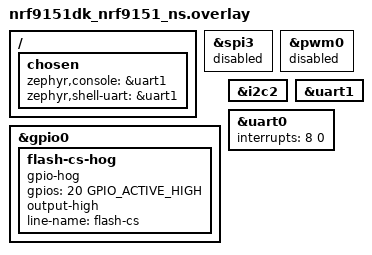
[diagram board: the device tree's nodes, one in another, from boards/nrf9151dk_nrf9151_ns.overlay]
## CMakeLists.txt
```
cmake_minimum_required(VERSION 3.20.0)

find_package(Zephyr REQUIRED HINTS $ENV{ZEPHYR_BASE})
project(nodem_zephyr)

target_sources(app PRIVATE
    src/main.c
    src/config_store.c
    src/display_task.c
    src/heartbeat_task.c
    src/hub75_task.c
    src/log.c
    src/modem_task.c
    src/nodem_config.c
    src/nodem_listener.c
    src/nodem_task.c
    src/ota_store.c
    src/pkg_store.c
    src/uart_task.c
)

# modem_task.c embeds the TLS root CA as a byte array via `#include
# "gts-root-r4.pem.inc"` - generate that from the PEM checked in under cert/.
set(modem_cert_gen_dir ${CMAKE_CURRENT_BINARY_DIR}/certs)
zephyr_include_directories(${modem_cert_gen_dir})
generate_inc_file_for_target(
    app
    cert/gts-root-r4.pem
    ${modem_cert_gen_dir}/gts-root-r4.pem.inc
    )

# `nodem-ffi` is built separately (`cargo build -p nodem-ffi --release --target
# thumbv8m.main-none-eabihf`, driven by the top-level `cargo run` wrapper
# before `west build` runs) - it isn't a CMake-built target, just a prebuilt
# static library to link in.
# Soft-float target: this app doesn't enable CONFIG_FPU, so Zephyr's own
# build is soft-float too - a hard-float (`...eabihf`) build of nodem-ffi
# fails to link (`uses VFP register arguments` / ARM EABI attribute mismatch).
set(NODEM_FFI_LIB
    ${CMAKE_CURRENT_SOURCE_DIR}/../nodem-ffi/target/thumbv8m.main-none-eabi/release/libnodem_ffi.a)

if(NOT EXISTS ${NODEM_FFI_LIB})
  message(FATAL_ERROR "nodem-ffi not built yet - run `cargo build -p nodem-ffi --release --target thumbv8m.main-none-eabi` first (expected at ${NODEM_FFI_LIB})")
endif()

# `zephyr_library_import`'s registration (a CMake global property consumed
# while `find_package(Zephyr)` processes zephyr/CMakeLists.txt) resolves
# before this file runs, so a library added that way silently never reaches
# the final link. Use a plain CMake imported target + `target_link_libraries`
# instead, per zephyr/samples/application_development/external_lib.
add_library(nodem_ffi STATIC IMPORTED GLOBAL)
set_target_properties(nodem_ffi PROPERTIES IMPORTED_LOCATION ${NODEM_FFI_LIB})
target_link_libraries(app PUBLIC nodem_ffi)
```

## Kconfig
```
#
# App-specific Kconfig - custom options live here, then "source
# Kconfig.zephyr" below pulls in the rest of Zephyr's own tree (required
# boilerplate for any app-level Kconfig root - see
# nrf/cmake/modules/kconfig.cmake: an app's own Kconfig file, if present,
# becomes KCONFIG_ROOT wholesale, not an addition to Zephyr's default one).
#

menu "nodem-nrf9151"

choice APP_LOG_LEVEL
	prompt "Application log level (log.h's info/warn/error/debug macros)"
	default APP_LOG_LEVEL_DEBUG
	help
	  Each level compiles in itself and everything more severe, same as
	  the `log` crate's max_level_* features nodem-ffi's Cargo.toml
	  mirrors this with (see the Makefile's LOG_LEVEL switch) - dropped
	  levels compile away to nothing (log.h's macros expand to a bare
	  ((void)0), not a runtime-filtered call), actually shrinking flash
	  usage rather than just quieting the console.

config APP_LOG_LEVEL_DEBUG
	bool "Debug and above (debug/info/warn/error)"

config APP_LOG_LEVEL_INFO
	bool "Info and above (info/warn/error)"

config APP_LOG_LEVEL_WARN
	bool "Warn and above (warn/error)"

config APP_LOG_LEVEL_ERROR
	bool "Error only"

config APP_LOG_LEVEL_NONE
	bool "No logging at all"

endchoice

endmenu

menu "Zephyr Kernel"
source "Kconfig.zephyr"
endmenu
```

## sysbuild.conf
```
# Builds MCUboot as its own sysbuild image alongside zephyr-app, splitting
# flash into two 320KB OTA slots (mcuboot_primary/mcuboot_secondary - see
# pm_static.yml for how their size is controlled indirectly) instead of the
# single monolithic TF-M+app image this project shipped with before. This
# just makes the two slots and the bootloader that swaps between them exist;
# streaming an update into the secondary slot and requesting the upgrade is
# src/ota_store.c's job (driven by nodem-ffi's control.rs, "ota" uploads).
SB_CONFIG_BOOTLOADER_MCUBOOT=y

# NCS v3.4.1+: Partition Manager (what pm_static.yml configures) is being
# phased out in favor of devicetree-based partitioning, and is no longer
# enabled by default for nRF91 boards specifically (unlike other SoC
# families, which still default it on for now) - explicit opt-in required,
# or the build silently gets no pm_config.h and every PM_*_ADDRESS/PM_*_SIZE
# consumer (pkg_store.c, the nonsecure_storage/settings_storage layout below)
# fails to compile. Revisit this whole file when actually migrating to DTS
# partitioning (see nrf/doc/.../migration_partitions.rst and
# nrf/scripts/pm_to_dts.py in the SDK) rather than treating this as permanent.
SB_CONFIG_PARTITION_MANAGER=y
```

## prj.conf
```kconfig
# Render nodem-rs's DOM runtime to the physical SSD1306 over I2C, and bring
# up the nRF9151 modem (modem_task.c) to reach the status endpoint over TLS.

# No CONFIG_DISPLAY - display_task.c talks to the SSD1306 directly over
# CONFIG_I2C, bypassing Zephyr's display subsystem entirely (its built-in
# ssd1306 driver produced garbled output on this panel).
CONFIG_I2C=y
CONFIG_GPIO=y

# TF-M's PSA Protected Storage and Internal Trusted Storage services are on
# by default but unused here - config_store.c goes through Zephyr's own
# settings/NVS against the "settings_storage" partition directly, never PSA's
# storage APIs. Turning these off drops tfm_ps/tfm_its/tfm_otp_nv_counters
# (Protected Storage's rollback-counter backing) entirely, along with the
# 32KB-SPU-alignment padding forced around each of those three small
# partitions - see pm_static.yml's own notes on why that space matters. That
# reclaimed ~96KB is what makes the two 320KB OTA slots (sysbuild.conf) fit
# at all under v3.4.1's TF-M. Considered porting device_secret specifically
# to PSA Protected Storage instead (real TF-M feature, would give it
# confidentiality/rollback protection) but decided against it: it costs back
# the same ~96KB, and its threat model (protects against a compromised NS
# app or flash-dump extraction) is largely moot anyway while
# UICR.APPROTECT/SECUREAPPROTECT are both left open for debugging (Makefile) -
# a physical SWD debugger can already read Secure flash/RAM directly. Staying
# on Zephyr's own settings/NVS.
CONFIG_TFM_PARTITION_PROTECTED_STORAGE=n
CONFIG_TFM_PARTITION_INTERNAL_TRUSTED_STORAGE=n

# TF-M's secure RAM - NCS's generic nRF91 default is 0x16000 (88KB), but
# this build's TF-M only statically uses ~37KB of it (all of it static: its
# stacks and mbedTLS heap included - see tfm_s.elf), mostly the crypto
# service (partition stack, mbedTLS heap, operation slots, iovec buffer),
# which this firmware barely uses (TLS is offloaded to the modem; only
# SHA-1 for the websocket handshake and RNG go through it). 48KB keeps
# ~11KB of headroom and is a multiple of the SPU's 8KB RAM region size
# (CONFIG_NRF_SPU_RAM_REGION_SIZE), which the secure/non-secure boundary
# has to fall on; the other 40KB goes to the app.
CONFIG_PM_PARTITION_SIZE_TFM_SRAM=0xC000

# TF-M's flash partition - Partition Manager's default is 0x17E00 (96KB less
# the 512-byte MCUboot header, three of the SPU's 32KB flash regions -
# CONFIG_NRF_TRUSTZONE_FLASH_REGION_SIZE), but this build's tfm_s.bin is only
# ~64.4KB: two regions (0xFE00 after the header) hold it with ~600 bytes to
# spare. The partition sits inside the signed image (mcuboot_primary holds
# TF-M and the app together), so its padding counted against the slot
# limit just like code - this hands those ~32KB to the app instead. The
# slot boundaries themselves don't move, so OTA between builds with and
# without this works. If TF-M ever grows past 0xFE00 (an NCS update, a TF-M
# partition turned back on - see above), the build fails at link/PM time,
# not silently: raise this back to 0x17E00 then.
CONFIG_PM_PARTITION_SIZE_TFM=0xFE00

CONFIG_MAIN_STACK_SIZE=4096
CONFIG_HEAP_MEM_POOL_SIZE=2048

# boot_write_img_confirmed()/boot_is_img_confirmed() (<zephyr/dfu/mcuboot.h>,
# used by heartbeat_task.c) - after `make flash-ota SLOT=1` lands a pending
# ("test") swap in the secondary slot (see the Makefile's own note),
# MCUboot boots it once without marking it permanent; if it's never
# confirmed before the next reset, MCUboot reverts back to the previous
# image automatically. This is what lets the new image call
# boot_write_img_confirmed() itself once it's proven stable, instead.
# IMG_MANAGER (the menuconfig gate) requires STREAM_FLASH; MCUBOOT_IMG_MANAGER
# is its only real choice and pulls in MCUBOOT_BOOTUTIL_LIB itself.
CONFIG_STREAM_FLASH=y
CONFIG_IMG_MANAGER=y
CONFIG_MCUBOOT_IMG_MANAGER=y
# ota_store.c erases mcuboot_secondary page by page as an upload streams in
# (and scrambles its MCUboot trailer before the first write), instead of
# erasing the whole 320KB slot up front - that takes several seconds, long
# enough to stall the uploader waiting for its CTR reply. Selects
# STREAM_FLASH_ERASE itself.
CONFIG_IMG_ERASE_PROGRESSIVELY=y

# nodem_listener.c's nodem_hw_reset() (the "#reset" command, via nodem-ffi's
# control.rs) needs sys_reboot().
CONFIG_REBOOT=y

# config_store.c - small flash-backed key/value store for persisted config
# (Settings on top of NVS). Enabling CONFIG_SETTINGS_NVS makes the partition
# manager reserve a "settings_storage" flash partition automatically - its
# address/size are pinned in pm_static.yml now (moved to reclaim what used
# to be pure alignment padding), but nothing here needed to change for that.
CONFIG_SETTINGS=y
CONFIG_SETTINGS_NVS=y
CONFIG_NVS=y
CONFIG_FLASH_MAP=y
CONFIG_FLASH=y

# pkg_store.c - raw staging partition for an uploaded nodem-rs binary
# UI/Media package (see pm_static.yml's "pkg" partition and control.rs's
# IControlLoader impl).
# CONFIG_FLASH_PAGE_LAYOUT is needed for flash_get_page_info_by_offs(), used
# there to find the flash's actual erase-page size rather than assuming one.
CONFIG_FLASH_PAGE_LAYOUT=y

# Modem library - modem_task.c calls nrf_modem_lib_init() itself (rather
# than relying on any auto-init), so enabling this alone doesn't touch the
# modem before main() runs.
CONFIG_NRF_MODEM_LIB=y

# LTE link control (registration/PDN bring-up) and the PDN library (default
# context activation events), used by modem_task.c to connect and to check
# SIM readiness (AT+CPIN? via nrf_modem_at.h) while offline.
CONFIG_LTE_LINK_CONTROL=y
CONFIG_LTE_LC_PDN_MODULE=y
CONFIG_LTE_LC_PDN_ESM_STRERROR=y

# Provisions the TLS root CA to the modem's key storage (modem-offloaded
# TLS - see IPPROTO_TLS_1_2 below - rather than a host-side TLS stack).
CONFIG_MODEM_KEY_MGMT=y

# Networking - offloaded sockets (the nRF9151 modem does TCP/TLS/DNS
# itself), no native netif needed.
CONFIG_NETWORKING=y
CONFIG_NET_NATIVE=n
CONFIG_NET_SOCKETS=y
CONFIG_NET_SOCKETS_OFFLOAD=y
CONFIG_NET_IPV4=y
CONFIG_NET_IPV6=y
CONFIG_POSIX_API=y

# Websocket client - modem_task.c's step_websocket_connect() layers this on
# top of the same offloaded TLS socket used for registration. NCS v3.4.1's
# Zephyr rewrote the RFC 6455 handshake to validate Sec-WebSocket-Accept via
# psa_hash_compute(PSA_ALG_SHA_1, ...) instead of calling mbedtls_sha1()
# directly like the older Zephyr this project shipped against under NCS
# v2.8.0 did (that older direct-call approach was why this project carried
# its own src/sha1_shim.c providing a standalone mbedtls_sha1() - removed
# now that nothing calls it anymore, see git history if ever needed again).
# PSA builds only compile in algorithms explicitly requested, and SHA-1 was
# never requested (only CONFIG_PSA_WANT_ALG_SHA_256, for TLS) since the old
# code path bypassed PSA for this entirely - without this,
# psa_hash_compute(PSA_ALG_SHA_1, ...) fails with PSA_ERROR_NOT_SUPPORTED,
# which websocket_connect() surfaces as -EPROTO.
CONFIG_PSA_WANT_ALG_SHA_1=y
CONFIG_WEBSOCKET_CLIENT=y

# printk() over the DK's onboard UART console - moved to uart1 (the board
# overlay's `chosen` override), wired through the J-Link's second USB
# virtual COM port (VCOM1), separate from both the SWD debug port and the
# process_command UART (uart0, see uart_task.c). RTT was abandoned: it
# requires an open SWD connection, which this board's TF-M setup re-locks
# on every boot, making RTT capture impossible without erasing (and thus
# stopping) the firmware each time. UART works regardless of the debug
# port's lock state.
CONFIG_SERIAL=y
CONFIG_CONSOLE=y
CONFIG_UART_CONSOLE=y

# Dedicated process_command UART (uart0) - interrupt-driven RX so
# uart_task.c's ISR can drain the FIFO into a ring buffer without losing
# bytes; nRF's UARTE has no real RX FIFO depth, so anything less than
# interrupt-driven (e.g. plain polling) drops bytes at any real baud rate.
CONFIG_UART_INTERRUPT_DRIVEN=y
CONFIG_RING_BUFFER=y
```

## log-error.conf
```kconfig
# Opt-in build fragment: drop debug()/info()/warn()-level logging, keep only
# error(). See zephyr-app/Kconfig (APP_LOG_LEVEL choice) and log.h. Applied
# via `LOG_LEVEL=error make build` (see the Makefile).
CONFIG_APP_LOG_LEVEL_ERROR=y
```

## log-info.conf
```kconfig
# Opt-in build fragment: drop debug()-level logging, keep info/warn/error.
# See zephyr-app/Kconfig (APP_LOG_LEVEL choice) and log.h. Applied via
# `LOG_LEVEL=info make build` (see the Makefile).
CONFIG_APP_LOG_LEVEL_INFO=y
```

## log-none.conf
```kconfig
# Opt-in build fragment: drop all of debug()/info()/warn()/error() logging
# and log_bytes(). See zephyr-app/Kconfig (APP_LOG_LEVEL choice) and log.h.
# Applied via `LOG_LEVEL=none make build` (see the Makefile).
CONFIG_APP_LOG_LEVEL_NONE=y
```

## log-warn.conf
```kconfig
# Opt-in build fragment: drop debug()/info()-level logging, keep warn/error.
# See zephyr-app/Kconfig (APP_LOG_LEVEL choice) and log.h. Applied via
# `LOG_LEVEL=warn make build` (see the Makefile).
CONFIG_APP_LOG_LEVEL_WARN=y
```

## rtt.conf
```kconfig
# Opt-in build fragment: view logs over RTT/SWD (`make logs-rtt`) instead of
# the default UART console (`make logs`). Applied on top of prj.conf via
# `-DEXTRA_CONF_FILE=rtt.conf` (see the Makefile's build-rtt target) into a
# separate build directory - the plain `make build`/`make logs` UART flow is
# untouched and stays the default; this is a second, parallel option, not a
# replacement.
#
# Needs CONFIG_UART_CONSOLE explicitly off: Zephyr's console drivers each
# install their own printk hook at init, so whichever one initializes last
# silently wins if both are left enabled - rather than depend on init-order
# behavior, this build variant is RTT-only.
#
# This only became viable once the debug port reliably stays open across a
# reset (see the Makefile's own note on UICR.APPROTECT/SECUREAPPROTECT) -
# RTT needs a live, unlocked SWD connection to read the target's RAM ring
# buffer, which is exactly what used to be locked after every boot.
CONFIG_USE_SEGGER_RTT=y
CONFIG_RTT_CONSOLE=y
CONFIG_UART_CONSOLE=n
```

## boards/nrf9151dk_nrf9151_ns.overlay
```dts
/*
 * spi3 (arduino_spi, enabled by default on this board) would claim
 * P0.11-P0.13 - disabled so those pins stay free for the HUB75 lines.
 * The DK's external flash still sits on them (CS = P0.20, flash node is
 * disabled in the base board dts).
 */
&spi3 {
	status = "disabled";
};

/* ...so hold the flash's CS high, or it could answer on P0.12 while the
 * HUB75 lines on P0.11-P0.13 are switching (see hub75_task.h). */
&gpio0 {
	flash-cs-hog {
		gpio-hog;
		gpios = <20 GPIO_ACTIVE_HIGH>;
		output-high;
		line-name = "flash-cs";
	};
};

/* P0.00 (pwm_led0, LED1) is HUB75's R1 - nothing uses pwm0, and a second
 * PWM instance claiming the same pin would fight hub75_task's. LED1 stays
 * main.c's heartbeat, as a plain GPIO (led0). */
&pwm0 {
	status = "disabled";
};

/* SSD1306 OLED on the board's arduino_i2c bus: P0.30 (SDA) / P0.31 (SCL),
 * Arduino D14/D15 - pinctrl and clock-frequency (I2C_BITRATE_FAST) already
 * come from the base board dts. No `ssd1306` child node here -
 * display_task.c talks to the panel directly over this bus with its own
 * hand-rolled driver. */
&i2c2 {
	status = "okay";
};

/* P0.28 (RX) / P0.29 (TX) - disabled by default on the `_ns` target ("used
 * by default in TF-M" per the base board dts), otherwise free. Pinctrl and
 * current-speed (115200) are already set correctly at the common board
 * level; this just re-enables it. Dedicated to console/log output only
 * (see log.h/prj.conf) - the `chosen` override below moves it here from
 * uart0, which is now dedicated to the process_command protocol instead
 * (see uart_task.c), so log text can never corrupt that protocol's framing
 * either way. */
&uart1 {
	status = "okay";
};

/* The process_command UART's (see uart_task.c) interrupt above everything
 * else: nRF's UARTE has next to no RX FIFO, and hub75_task.c's PWM interrupt
 * (priority 1, the same level this had by default, so it couldn't be preempted)
 * renders a whole row per run - long enough at full baud for the next bytes
 * to be lost, which stalled every upload ("pkg"/"ota") of more than a few KB. */
&uart0 {
	interrupts = <8 0>;
};

/ {
	chosen {
		zephyr,console = &uart1;
		zephyr,shell-uart = &uart1;
	};
};
```

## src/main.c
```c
/*
 * Entry point. The real work happens in display_task.c (owns the SSD1306
 * over I2C), nodem_task.c (renders nodem-rs at ~30Hz and hands frames to
 * display_task), and modem_task.c (LTE/TLS) - all self-start via
 * K_THREAD_DEFINE at kernel init, before main() runs. This initializes the
 * config store first (so those threads never race its first load), then
 * just blinks the LED as a liveness heartbeat.
 */

#include <zephyr/kernel.h>
#include <zephyr/device.h>
#include <zephyr/devicetree.h>
#include <zephyr/dfu/mcuboot.h>
#include <zephyr/drivers/gpio.h>

#include "config_store.h"
#include "heartbeat_task.h"
#include "log.h"

#define TAG "main"

#define LED0_NODE DT_ALIAS(led0)
static const struct gpio_dt_spec led = GPIO_DT_SPEC_GET(LED0_NODE, gpios);

int main(void)
{
	info(TAG, "main() entered");

	/* MCUboot always executes from the primary slot - there's no "running
	 * from slot 1" to report post-swap, the swap physically moves bytes
	 * into slot 0 before this ever runs. What *is* knowable: whether this
	 * boot is a freshly-swapped-in OTA image MCUboot is still only
	 * running as a one-time test (boot_is_img_confirmed() == false, see
	 * the Makefile's `flash-ota SLOT=1` and heartbeat_task.c's own note),
	 * or an already-confirmed image (either the original factory image,
	 * or a previously-confirmed OTA update - the two are indistinguishable
	 * from here once confirmed, since confirming doesn't record *when*). */
	if (boot_is_img_confirmed()) {
		info(TAG, "boot: image confirmed");
	} else {
		info(TAG, "boot: image pending - OTA test swap, reverts if not confirmed within %ds",
		     HEARTBEAT_OTA_CONFIRM_SECONDS);
	}

	int err = config_store_init();

	if (err) {
		error(TAG, "config_store_init failed, err %d", err);
	}

	if (!gpio_is_ready_dt(&led)) {
		error(TAG, "led device not ready");
		return 0;
	}
	gpio_pin_configure_dt(&led, GPIO_OUTPUT_INACTIVE);

	while (true) {
		gpio_pin_toggle_dt(&led);
		k_msleep(500);
	}

	return 0;
}
```

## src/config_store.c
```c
#include "config_store.h"

#include <string.h>
#include <stdio.h>
#include <errno.h>

#include <zephyr/kernel.h>
#include <zephyr/settings/settings.h>

#include "log.h"

#define TAG "config"

#define MAX_ENTRIES 16
#define MAX_KEY_LEN 15
#define MAX_STR_LEN 127

enum entry_type {
	ENTRY_STR,
	ENTRY_I32,
};

struct entry {
	bool used;
	enum entry_type type;
	char key[MAX_KEY_LEN + 1];
	union {
		char str[MAX_STR_LEN + 1];
		int32_t i32;
	} value;
};

static struct entry entries[MAX_ENTRIES];
static K_MUTEX_DEFINE(entries_lock);

/* Caller must hold entries_lock. Returns the existing entry for `key`/`type`,
 * or - if `create` - a freshly claimed one, or NULL if not found/no room. */
static struct entry *find_entry(const char *key, enum entry_type type, bool create)
{
	struct entry *free_slot = NULL;

	for (int i = 0; i < MAX_ENTRIES; i++) {
		if (entries[i].used && entries[i].type == type &&
		    strcmp(entries[i].key, key) == 0) {
			return &entries[i];
		}
		if (!entries[i].used && !free_slot) {
			free_slot = &entries[i];
		}
	}

	if (!create || !free_slot) {
		return NULL;
	}

	strncpy(free_slot->key, key, MAX_KEY_LEN);
	free_slot->key[MAX_KEY_LEN] = '\0';
	free_slot->type = type;
	free_slot->used = true;

	return free_slot;
}

static int settings_set(const char *name, size_t len, settings_read_cb read_cb, void *cb_arg)
{
	const char *sub_key;

	k_mutex_lock(&entries_lock, K_FOREVER);

	if (settings_name_steq(name, "s", &sub_key) && sub_key) {
		char buf[MAX_STR_LEN + 1] = { 0 };
		ssize_t n = read_cb(cb_arg, buf, sizeof(buf) - 1);
		struct entry *e;

		if (n < 0) {
			k_mutex_unlock(&entries_lock);
			return n;
		}

		e = find_entry(sub_key, ENTRY_STR, true);
		if (!e) {
			k_mutex_unlock(&entries_lock);
			return -ENOMEM;
		}

		memcpy(e->value.str, buf, sizeof(e->value.str));
		k_mutex_unlock(&entries_lock);
		return 0;
	}

	if (settings_name_steq(name, "i", &sub_key) && sub_key) {
		int32_t val;
		ssize_t n = read_cb(cb_arg, &val, sizeof(val));
		struct entry *e;

		if (n != sizeof(val)) {
			k_mutex_unlock(&entries_lock);
			return -EINVAL;
		}

		e = find_entry(sub_key, ENTRY_I32, true);
		if (!e) {
			k_mutex_unlock(&entries_lock);
			return -ENOMEM;
		}

		e->value.i32 = val;
		k_mutex_unlock(&entries_lock);
		return 0;
	}

	k_mutex_unlock(&entries_lock);
	return -ENOENT;
}

SETTINGS_STATIC_HANDLER_DEFINE(config_store, "cfg", NULL, settings_set, NULL, NULL);

void config_get_str(const char *key, char *buf, size_t buf_len, const char *default_val)
{
	const char *src = default_val;

	k_mutex_lock(&entries_lock, K_FOREVER);

	struct entry *e = find_entry(key, ENTRY_STR, false);

	if (e) {
		src = e->value.str;
	}

	strncpy(buf, src, buf_len - 1);
	buf[buf_len - 1] = '\0';

	k_mutex_unlock(&entries_lock);
}

int config_set_str(const char *key, const char *val)
{
	if (strlen(key) > MAX_KEY_LEN || strlen(val) > MAX_STR_LEN) {
		return -EINVAL;
	}

	k_mutex_lock(&entries_lock, K_FOREVER);

	struct entry *e = find_entry(key, ENTRY_STR, true);

	if (!e) {
		k_mutex_unlock(&entries_lock);
		return -ENOMEM;
	}

	strncpy(e->value.str, val, MAX_STR_LEN);
	e->value.str[MAX_STR_LEN] = '\0';

	char full_key[8 + MAX_KEY_LEN + 1];

	snprintf(full_key, sizeof(full_key), "cfg/s/%s", key);

	int err = settings_save_one(full_key, e->value.str, strlen(e->value.str) + 1);

	info(TAG, "settings_save_one('%s') -> %d", full_key, err);

	k_mutex_unlock(&entries_lock);
	return err;
}

int32_t config_get_i32(const char *key, int32_t default_val)
{
	k_mutex_lock(&entries_lock, K_FOREVER);

	struct entry *e = find_entry(key, ENTRY_I32, false);
	int32_t val = e ? e->value.i32 : default_val;

	k_mutex_unlock(&entries_lock);
	return val;
}

int config_set_i32(const char *key, int32_t val)
{
	if (strlen(key) > MAX_KEY_LEN) {
		return -EINVAL;
	}

	k_mutex_lock(&entries_lock, K_FOREVER);

	struct entry *e = find_entry(key, ENTRY_I32, true);

	if (!e) {
		k_mutex_unlock(&entries_lock);
		return -ENOMEM;
	}

	e->value.i32 = val;

	char full_key[8 + MAX_KEY_LEN + 1];

	snprintf(full_key, sizeof(full_key), "cfg/i/%s", key);

	int err = settings_save_one(full_key, &val, sizeof(val));

	info(TAG, "settings_save_one('%s') -> %d", full_key, err);

	k_mutex_unlock(&entries_lock);
	return err;
}

size_t config_list(char *buf, size_t buf_len)
{
	size_t off = 0;

	k_mutex_lock(&entries_lock, K_FOREVER);

	for (int i = 0; i < MAX_ENTRIES; i++) {
		if (!entries[i].used) {
			continue;
		}

		int n = entries[i].type == ENTRY_STR
				? snprintf(&buf[off], buf_len - off, "%s=%s\r\n", entries[i].key,
					   entries[i].value.str)
				: snprintf(&buf[off], buf_len - off, "%s=%d\r\n", entries[i].key,
					   entries[i].value.i32);

		if (n < 0 || (size_t)n >= buf_len - off) {
			break;
		}

		off += (size_t)n;
	}

	k_mutex_unlock(&entries_lock);
	return off;
}

int config_store_init(void)
{
	int err = settings_subsys_init();

	if (err) {
		error(TAG, "settings_subsys_init failed, err %d", err);
		return err;
	}

	err = settings_load();
	if (err) {
		error(TAG, "settings_load failed, err %d", err);
		return err;
	}

	return 0;
}
```

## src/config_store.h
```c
#ifndef CONFIG_STORE_H_
#define CONFIG_STORE_H_

#include <stddef.h>
#include <stdint.h>

/*
 * Small flash-backed key/value store (Zephyr Settings on top of NVS, in the
 * "settings_storage" flash partition partition manager reserves once
 * CONFIG_SETTINGS_NVS is enabled - see prj.conf) for the handful of small
 * strings and numbers this firmware needs to persist across reboots (e.g. a
 * provisioned APN override, a retry count).
 *
 * All persisted keys are loaded into a small RAM cache at config_store_init()
 * (via settings_load()), so config_get_str()/config_get_i32() during normal
 * operation are just a RAM lookup, not a flash read. config_set_str()/
 * config_set_i32() update the cache and write through to flash immediately -
 * call them only when a value actually changes, not on a hot path.
 */

/* Must be called once at startup, before any other thread reads config
 * (main() does this before starting anything else). */
int config_store_init(void);

/* Copies the string stored under `key` into `buf` (always NUL-terminated,
 * truncated to fit `buf_len` if necessary), or `default_val` if `key` has
 * never been set. */
void config_get_str(const char *key, char *buf, size_t buf_len, const char *default_val);

/* Persists `val` under `key`. Returns 0 on success, a negative errno
 * otherwise. */
int config_set_str(const char *key, const char *val);

/* Returns the number stored under `key`, or `default_val` if it has never
 * been set. */
int32_t config_get_i32(const char *key, int32_t default_val);

/* Persists `val` under `key`. Returns 0 on success, a negative errno
 * otherwise. */
int config_set_i32(const char *key, int32_t val);

/* Formats every stored entry as "key=value\r\n" (strings as-is, numbers as
 * decimal) into `buf`, stopping (without emitting a partial line) once an
 * entry wouldn't fit rather than overflowing - see control.rs's "#nvs".
 * Returns the number of bytes written; `buf` is not NUL-terminated. */
size_t config_list(char *buf, size_t buf_len);

#endif /* CONFIG_STORE_H_ */
```

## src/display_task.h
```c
#ifndef DISPLAY_TASK_H_
#define DISPLAY_TASK_H_

#include <stddef.h>
#include <stdint.h>

#include "nodem_config.h"

/*
 * Hands display_task nodem-rs's framebuffer `buf` (row-major, MSB first -
 * bit index = y * width + x) and the config it's rendered with, and marks
 * it dirty for display_task to flush to the panel on its next cycle.
 * display_task reads `buf` in place - no copy - so it must stay valid (a
 * later call replaces it), and every write to it must happen between
 * display_fb_lock()/display_fb_unlock(). display_task maps it onto the
 * configured panel itself, through the config's "oled" entry (see
 * nodem_config.h) and the panel's own size/offset/rotation (see
 * display_oled_set()).
 */
void display_task_submit(const uint8_t *buf, const struct nodem_config *config);

/*
 * Held around anything that writes the framebuffer passed to
 * display_task_submit() (a whole render, a resize) - display_task only
 * ever reads it under the same lock, one page at a time, so a page is
 * never built from a half-rendered frame.
 */
void display_fb_lock(void);
void display_fb_unlock(void);

/*
 * Validates and persists config_store's "oled" key, then has display_task
 * tear down the current panel and bring it up anew with it right away.
 * Same format as nodem-esp32's oled.rs (OledConfig):
 * "<protocol>:<width>:<height>:<x>:<y>[:<rotation>]", default
 * "ssd1306:128:64:0:0". `ssd1306` is the only protocol; <width>x<height>
 * is the panel's own size (128x64, 128x32, 96x16, 72x40, 64x48 or 64x32),
 * <x> (0-127) the start column in the controller's display RAM, <y> (0-63)
 * its display offset register (a vertical shift, per row - unlike
 * nodem-esp32, not limited to multiples of 8), <rotation> 0/90/180/270
 * clockwise, done by the controller's column/row flips (90/270 also need
 * a software transpose, which the controller can't do). All of it is set
 * on the controller on every (re)initialization. An empty value or any
 * other protocol disables the display (stored as given). A valid
 * "ssd1306" value is stored normalized (rotation only when non-zero).
 *
 * Returns 0 on success, -EINVAL for a malformed "ssd1306" value (nothing
 * stored), or config_store's error if persisting it failed.
 */
int display_oled_set(const char *value);

#endif /* DISPLAY_TASK_H_ */
```

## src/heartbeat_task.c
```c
#include "heartbeat_task.h"

#include <zephyr/dfu/mcuboot.h>
#include <zephyr/kernel.h>

#include "modem_task.h"
#include "log.h"

#define TAG "heartbeat"

#define HEARTBEAT_PERIOD_MS (5 * MSEC_PER_SEC)

/* How long a freshly-swapped-in OTA image (see the Makefile's `flash-ota
 * SLOT=1`) runs before this confirms it permanent. MCUboot boots a pending
 * ("test") image only once - if it's never confirmed before the next
 * reset, MCUboot reverts back to the previous image on its own. 60s is
 * comfortably past modem_task's own connection/registration steps, so
 * "stable" here really means "got at least one full connection cycle in",
 * not just "didn't crash immediately". */
#define OTA_CONFIRM_UPTIME_MS (HEARTBEAT_OTA_CONFIRM_SECONDS * MSEC_PER_SEC)

/* Runs at most once per boot (guarded by ota_confirmed, not just by the
 * uptime check re-passing every loop once true) - boot_write_img_confirmed()
 * is a flash write, not something to repeat every 5s once already done. */
static void ota_confirm_if_due(void)
{
	static bool ota_confirmed;

	if (ota_confirmed || k_uptime_get() < OTA_CONFIRM_UPTIME_MS) {
		return;
	}

	ota_confirmed = true;

	if (boot_is_img_confirmed()) {
		return;
	}

	int err = boot_write_img_confirmed();

	if (err) {
		error(TAG, "boot_write_img_confirmed failed, err %d", err);
	} else {
		info(TAG, "image confirmed permanent - rollback disabled");
	}
}

static void heartbeat_task(void *p1, void *p2, void *p3)
{
	ARG_UNUSED(p1);
	ARG_UNUSED(p2);
	ARG_UNUSED(p3);

	char buf[224];

	while (true) {
		modem_status_format(buf, sizeof(buf));
		info(TAG, "%s", buf);

		ota_confirm_if_due();

		k_msleep(HEARTBEAT_PERIOD_MS);
	}
}

#define HEARTBEAT_STACK_SIZE 1024
#define HEARTBEAT_PRIORITY   7

K_THREAD_DEFINE(heartbeat_tid, HEARTBEAT_STACK_SIZE, heartbeat_task, NULL, NULL, NULL,
		 HEARTBEAT_PRIORITY, 0, 0);
```

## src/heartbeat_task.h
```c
#ifndef HEARTBEAT_TASK_H_
#define HEARTBEAT_TASK_H_

/*
 * Matches nodem-esp32's heartbeat.rs: a low-frequency (5s) liveness log
 * distinct from modem_task.c's own 5Hz status line - this is meant for a
 * human periodically glancing at the console, not the fast, complete status
 * dump. Currently just modem_status_format()'s summary; nodem-esp32's own
 * heartbeat_task also logs Wi-Fi status, which this project has no
 * equivalent of. Self-starting (K_THREAD_DEFINE) - no public API needed
 * beyond this file existing in the build.
 *
 * Also owns confirming a pending OTA swap permanent after
 * OTA_CONFIRM_UPTIME_MS of uptime (see ota_confirm_if_due() in the .c file)
 * - piggybacking on this task's own periodic wake rather than a separate
 * thread, since "has this task been looping normally" is itself a
 * reasonable-enough stability signal for a single-purpose device like this.
 */

/* Shared with main.c's boot-time log and modem_task.c's status message, so
 * both mention the same number ota_confirm_if_due() actually uses rather
 * than a copy that could drift out of sync with it. */
#define HEARTBEAT_OTA_CONFIRM_SECONDS 60

#endif /* HEARTBEAT_TASK_H_ */
```

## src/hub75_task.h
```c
#ifndef HUB75_TASK_H_
#define HUB75_TASK_H_

#include <stddef.h>
#include <stdint.h>

#include "nodem_config.h"

/*
 * HUB75 RGB LED matrix driver. There's no GPIO-port DMA on the nRF91, so
 * the column data is shifted out by two PWM instances in Individual
 * decoder mode, used as a 4-bit parallel port each: EasyDMA loads one
 * 16-bit value per channel per PWM period, and every value is either
 * "low all period" or "high all period" - except CLK, which rises
 * mid-period, while the data lines are stable. Both instances run off the
 * same 16MHz clock and are started back to back, so they stay in step to
 * within a tick or two. OE rides on PWM2's spare channel, so brightness
 * (how long each row is lit) is timed by the same sequence, in PWM ticks,
 * not by interrupt latency.
 *
 * Laid out for a straight two-row ribbon to the HUB75 connector, with GND
 * next to P0.13 for its pins 4/8/16 (8 only on panels without E):
 *
 *   HUB75 pin:  1   3   5   7   9  11  13  15     2   6   8  10  12  14
 *   signal:     R1  B1  R2  B2  A  C   CLK OE     G1  G2  E  B   D   LAT
 *   nRF pin:    .00 .01 .02 .03 .04 .05 .06 .07   .08 .09 .10 .11 .12 .13
 *
 *   PWM1: R1, G1, B1, CLK - PWM2: R2, G2, B2, OE (active low) - GPIO: the
 *   rest. D only with 16 or 32 row addresses, E only with 32.
 *
 * P0.00/.01/.04/.05 are the DK's LED1-LED4 (LED1: main.c's heartbeat, see
 * hub75_task.c), P0.08/.09 its BUTTON1/BUTTON2 - pressing either while the
 * panel runs shorts that output to GND. The DK's external flash shares
 * P0.11-P0.13 with B/D/LAT, so the board overlay holds its CS (P0.20) high,
 * and the board's pwm0 (P0.00) is disabled there. While disabled, every one
 * of these pins is released (back to its reset state, an unconnected input)
 * - except OE, held high so the panel stays blanked rather than showing
 * whatever it last latched, and P0.00, a plain output for the heartbeat.
 *
 * One row address is shifted per PWM sequence. With fewer row addresses
 * than rows per half (a 1/8-scan 64x32 panel: 8 addresses, 16 rows per
 * half), each address's chain runs through several panel rows, one panel
 * width each - see frame_set_pixel() for the order. When both instances
 * stop at its end (OE falls back to its GPIO level, high - blanked), the
 * PWM1 interrupt selects that row's address, latches it, and starts
 * shifting the next row, during which OE lights the latched one for a
 * brightness-dependent part of the shift time. Rows are rendered one ahead
 * by the interrupt itself, into the other of two ping-ponged row buffers.
 *
 * Self-starting (K_THREAD_DEFINE), configured through config_store's
 * "hub75" (see hub75_config_set()). Shows nodem's framebuffer through the
 * "nodem" config's "hub75" entry (placement and scaling, same as the
 * OLED's - see nodem_config.h), lit pixels in the configured colour, unlit
 * ones in the off colour; without an entry, the same blinking dotted edge
 * the OLED shows.
 */

/* A sanity limit on the display's size (64x256, 128x128, ...) - how much
 * of it is actually driven depends on the memory there is, see
 * hub75_task.c's hub75_alloc(). */
#define HUB75_MAX_PIXELS 16384

/* Brightness range: the share of each row's time it's lit for, out of this
 * (OE duty cycle, in PWM ticks - finer than 8 bits on every panel size). */
#define HUB75_BRIGHTNESS_MAX 0x7FFF

/* What a never-configured device uses (and persists): this DK's 64x32 1/8
 * scan panel, input connector on the right, plain shift-register drivers,
 * red, at a low brightness (~1.6%). hub75_task.c's hub75_default() is the
 * same, parsed. */
#define HUB75_DEFAULT "64:32:rt:1x1,8:n:500:shift:4,#ff0000,#000000,512"

/*
 * Validates and persists config_store's "hub75" and has hub75_task apply it
 * right away. The format is
 *
 *   <geometry>,<protocol>,<color>,<off_color>,<brightness>
 *
 * - <geometry>: "<width>:<height>:<layout>[:<grid>]" - the whole display.
 *   <layout> is up to two order-independent letters, "l"/"r" (the input
 *   connector's side, seen from the front) and "t"/"b" (row 0 at the top
 *   or the bottom) - "rb" is a panel mounted upside down. Each defaults to
 *   "l"/"t". <grid> is "<cols>x<rows>[i]" (default "1x1", at most 16
 *   panels; a lone number is that many side by side): the display is a
 *   grid of that many equal panels on one chain, which - seen with the
 *   layout's mirroring applied - enters at the top left, runs through the
 *   top row of panels, then the next one. With "i" (serpentine), every
 *   second row of panels is mounted upside down and the chain runs back
 *   through it, so each panel's output is right next to the next one's
 *   input. Two panels stacked, entering at the top right: "rt:1x2i".
 * - <protocol>: a preset - "4s", "8s", "8sf", "16s", "32s" (the number of
 *   row addresses; "8sf": chain "f") - or
 *   "<scan>:<chain>:<clock_khz>:<chip>:<depth>", each part optional:
 *   - <scan>: row addresses - 2 (A), 4 (A-B), 8 (A-C), 16 (A-D) or 32
 *     (A-E). On a panel with fewer row addresses than rows per half
 *     (labels like "8S" on a 32-row panel), each address's chain runs
 *     through several rows - see <chain>.
 *   - <chain>: "<n|f>[<segment>][z]" - how it does: one piece of
 *     <segment> columns (default: a whole panel width) per row in turn,
 *     the first row's nearest the input ("n") or furthest ("f"), every
 *     second piece backwards with "z". Most panels are "n" or "f"; 1/4
 *     and some 1/8 scan ones interleave in 8- or 16-column pieces ("n8",
 *     "f16z", ...). Ignored with one row per address.
 *   - <clock_khz>: the pixel clock, 100-1000 kHz.
 *   - <chip>: the column driver - "shift" (plain shift registers: ICN2037,
 *     ICN2038, MBI5124, DP5125, ...) or "fm6126a" (also "fm6124",
 *     "icn2038s"; set up with a register write before anything shows).
 *   - <depth>: bits per colour channel, 1-8 (2-256 levels each, 8 to 16.7
 *     million colours). Each bit is one more shift of every row (a bit plane, lit
 *     for its binary weight), so the refresh rate divides by it - 4 bits
 *     on two 64x32 1/8 scan panels at 500 kHz is ~60 Hz; the CPU time
 *     doesn't change (one render per shift either way).
 *   Presets set every part (500 kHz, "shift", 4 bits).
 * - <color>/<off_color>: for lit/unlit pixels, "#rrggbb" (shorter is
 *   fine - missing digits are 0) or an effect, "<effect>[:<speed>]":
 *   "plasma" (moving waves of colour, formerly "rainbow"), "stripes"
 *   (diagonal, scrolling - a barber pole), "wave" (horizontal bands waving
 *   like a flag), "scroll"
 *   (vertical bands sliding sideways), "cycle" (one colour for the whole
 *   panel, blending round the wheel), "fade" (each colour in turn, fading
 *   in from black and out again), "fire" (flickering red/yellow/white
 *   rising from the bottom), "sparkle" (every pixel twinkling - fading in and out in a
 *   random colour, at its own time), "ripple" (rings spreading from the centre) or "gradient"
 *   (a still diagonal rainbow). The full form is
 *   "<effect>[:<speed>[:<palette>[:<scale>]]]", an empty part its
 *   default: <speed> (1-32, default per effect - none for "gradient") is
 *   how far it moves per frame, at 25 frames a second; <palette> (up to 8
 *   of k r g y b m c w - black, red, green, yellow, blue, magenta, cyan,
 *   white) the colours it blends between, in order and in equal shares,
 *   as a loop - "fire": a ramp, coldest first - repeats allowed (default: the six colours of the wheel; for "fire" "kryw",
 *   coldest to hottest; for "sparkle" the wheel and white); <scale> (1-32,
 *   default 8) the pattern's size, larger stretching it. E.g.
 *   "ripple:4:rb", "plasma::cg:16", "fire:::4".
 *   "#rrggbb" and the effects' blends go through gamma 2 to <depth> bits
 *   per channel - at depth 1, every blend is back to bands of the palette's
 *   colours.
 * - <brightness>: 0-HUB75_BRIGHTNESS_MAX.
 *
 * Any field left empty (or missing at the end) takes HUB75_DEFAULT's. The
 * display must fit HUB75_MAX_PIXELS; as many of its panels as fit in the
 * driver's memory are driven (the first ones along the chain), the rest
 * stay blank - see the log. An empty value as a
 * whole disables the panel. Stored with every part spelled out, presets
 * expanded, so "#cfg" shows exactly what's in use. Returns 0 on success,
 * -EINVAL for a malformed value (nothing stored), or config_store's error
 * if persisting it failed.
 */
int hub75_config_set(const char *value);

/*
 * Hands hub75_task nodem-rs's framebuffer `buf` and the config it's
 * rendered with - same contract as display_task_submit(): read in place,
 * under display_fb_lock(), so it must stay valid until the next call. The
 * panel is redrawn from it after every call.
 */
void hub75_task_submit(const uint8_t *buf, const struct nodem_config *config);

/*
 * The "hub75" line of "#stat" (control.rs), shaped like nodem-esp32's
 * "oled" one: "hub75,0,," while disabled, else "hub75,1,<w>x<h>,<status>" -
 * status "ok", "low_mem <driven>/<configured> panels" (the memory was only
 * enough for some, the rest stay blank), "no_mem" (not even for one) or
 * "overload" (stopped after tripping too often - see hub75_task.c). No line
 * break. snprintf semantics: returns the untruncated length.
 */
size_t hub75_stat_format(char *buf, size_t buf_len);

/* Blanks the panel while `hold` is true and sets it up again from the config
 * once it is false. nodem_task.c holds it during a "pkg"/"ota" upload: the
 * PWM interrupt's row rendering overruns whenever the UART interrupt or a
 * flash write preempts it, and after a few overruns the panel switches itself
 * off until the config changes. */
void hub75_task_hold(bool hold);

#endif /* HUB75_TASK_H_ */
```

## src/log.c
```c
#include "log.h"

#include <ctype.h>
#include <stdbool.h>
#include <stdio.h>

/* Logs at info() level internally, so its own formatting work (below) is
 * skipped entirely - not just its output silenced - once the log level
 * drops below info, same reasoning as log.h's own macros. */
#if defined(CONFIG_APP_LOG_LEVEL_DEBUG) || defined(CONFIG_APP_LOG_LEVEL_INFO)
void log_bytes(const char *tag, const char *dir, const uint8_t *buf, size_t len)
{
	if (len == 0) {
		return;
	}

	/* Up to 16 "xx "-formatted bytes (8 + 8, split by a "... " gap marker
	 * once len > 16) plus a NUL. */
	char hex[3 * 16 + 4 + 1];
	size_t hex_len = 0;

	if (len <= 16) {
		for (size_t i = 0; i < len; i++) {
			hex_len += snprintf(&hex[hex_len], sizeof(hex) - hex_len, "%02x ", buf[i]);
		}
	} else {
		for (size_t i = 0; i < 8; i++) {
			hex_len += snprintf(&hex[hex_len], sizeof(hex) - hex_len, "%02x ", buf[i]);
		}
		hex_len += snprintf(&hex[hex_len], sizeof(hex) - hex_len, "... ");
		for (size_t i = len - 8; i < len; i++) {
			hex_len += snprintf(&hex[hex_len], sizeof(hex) - hex_len, "%02x ", buf[i]);
		}
	}

	size_t trimmed = len;
	bool truncated = false;

	for (size_t i = 0; i < len; i++) {
		if (buf[i] < 0x20 || buf[i] > 127) {
			trimmed = i;
			truncated = len > i + 2;
			break;
		}
	}	

	info(tag, "%s [%u] \"%.*s%s\" %s", dir, (unsigned)len, (int)trimmed, buf,
	     truncated ? "..." : "", hex);
}
#else
void log_bytes(const char *tag, const char *dir, const uint8_t *buf, size_t len)
{
	(void)tag;
	(void)dir;
	(void)buf;
	(void)len;
}
#endif
```

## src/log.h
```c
#ifndef LOG_H_
#define LOG_H_

#include <stddef.h>
#include <stdint.h>

#include <zephyr/kernel.h>

/*
 * Unified console log format across the whole firmware: "[TAG] LEVEL
 * message". Plain printk() macros rather than Zephyr's CONFIG_LOG subsystem
 * - this project logs over the DK's console UART (uart1 - see the board
 * overlay's `chosen` override and prj.conf), and the format is
 * fixed/simple enough not to need LOG's runtime filtering, deferred
 * logging, or multiple backends.
 *
 * Each macro compiles to a bare ((void)0) once CONFIG_APP_LOG_LEVEL_* (see
 * zephyr-app/Kconfig, set via the Makefile's LOG_LEVEL switch) drops below
 * it - a real compile-time removal (format string and all), not just a
 * runtime-filtered call that still costs flash either way.
 */
#if defined(CONFIG_APP_LOG_LEVEL_DEBUG)
#define debug(tag, fmt, ...) printk("[%s] DEBUG " fmt "\n", tag, ##__VA_ARGS__)
#else
#define debug(tag, fmt, ...) ((void)0)
#endif

#if defined(CONFIG_APP_LOG_LEVEL_DEBUG) || defined(CONFIG_APP_LOG_LEVEL_INFO)
#define info(tag, fmt, ...) printk("[%s] INFO " fmt "\n", tag, ##__VA_ARGS__)
#else
#define info(tag, fmt, ...) ((void)0)
#endif

#if defined(CONFIG_APP_LOG_LEVEL_DEBUG) || defined(CONFIG_APP_LOG_LEVEL_INFO) || \
	defined(CONFIG_APP_LOG_LEVEL_WARN)
#define warn(tag, fmt, ...) printk("[%s] WARN " fmt "\n", tag, ##__VA_ARGS__)
#else
#define warn(tag, fmt, ...) ((void)0)
#endif

#if !defined(CONFIG_APP_LOG_LEVEL_NONE)
#define error(tag, fmt, ...) printk("[%s] ERROR " fmt "\n", tag, ##__VA_ARGS__)
#else
#define error(tag, fmt, ...) ((void)0)
#endif

/*
 * Logs a byte buffer as `dir [<length>] "<trimmed ascii>" <hex>` at INFO
 * level - the ASCII preview is cut at the first '\r'/'\n' (with a "..."
 * marker) rather than embedding raw line breaks in the log, and any
 * trailing whitespace before that cut is trimmed too. The hex dump covers
 * the whole buffer if it's 16 bytes or fewer, otherwise just its first 8
 * and last 8 bytes (split by a "..." marker) - the two ends of a transfer
 * are usually what a bug shows up in, not the middle.
 */
void log_bytes(const char *tag, const char *dir, const uint8_t *buf, size_t len);

#endif /* LOG_H_ */
```

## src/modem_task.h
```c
#ifndef MODEM_TASK_H_
#define MODEM_TASK_H_

#include <stddef.h>
#include <stdint.h>

/*
 * Brings up the nRF9151 modem: modem library init, SIM readiness check
 * (plus CA cert provisioning, which must happen in the same offline window
 * as the SIM check - see modem_task.c), and LTE registration with the
 * default PDN context. That's as far as it goes while idle - a TLS
 * connection is only opened when there's an actual reason to: an "#reg"
 * (over UART, provisioning a registration code - see
 * config_store.h/control.rs) triggers a one-shot cloud registration
 * attempt, closed again immediately once it concludes; once registered
 * (a device id on file), it instead opens the device's persistent
 * websocket channel to the cloud (auth'd with the id/secret from
 * registration) and keeps it alive with a periodic ping, reconnecting if it
 * drops. Either way, nothing here holds a connection open (or spends any
 * bandwidth) with no work to do - PDN itself is kept up while idle since
 * LTE attach alone doesn't cost ongoing bandwidth.
 *
 * Runs the sequence continuously - a failed step is retried, and losing the
 * PDN connection drops back to reconnect it - while a second thread prints
 * a one-line status summary ("init=... sim=... pdn=... tls=... reg=...
 * ws=...") at 5Hz; heartbeat_task.c prints the same summary again, just
 * much less often, as a low-frequency liveness log (matching nodem-esp32's
 * heartbeat_task). Self-starting (K_THREAD_DEFINE).
 *
 * Once connected, the websocket also doubles as a second command transport
 * alongside uart_task.c's UART - modem_ws_read()/modem_ws_write() below are
 * nodem_task.c's nodem_process_ws()'s counterpart to
 * uart_task_read()/uart_task_write(), feeding the same
 * nodem_process_command() so "#..." commands work identically over either.
 */

/* Formats the current step statuses, e.g. "init=ok(0) sim=running(0)
 * pdn=ok(0) tls=pending(0) reg=pending(0) ws=pending(0) fd=-1 wsock=-1",
 * into `buf` (NUL-terminated, truncated to fit buf_len). Returns the length
 * the untruncated string would have been (snprintf semantics). */
size_t modem_status_format(char *buf, size_t buf_len);

/* Formats "#stat"'s modem and cloud lines (control.rs), matching
 * nodem-esp32's command_listener.rs "stat" shape:
 *   "modem,<state>,<apn>,<ip>,<rsrp dBm>,<error>\r\n"
 *   "cloud,<registration>,<connection>,<host>,<device_name>,<error>\r\n"
 * <state> is one of connecting/connected/failed, <registration> one of
 * no_reg (no registration code provisioned yet)/registering/registered/
 * reg_failed (the server rejected the code, or the latest attempt failed
 * and is waiting to be retried), <connection> one of
 * disconnected/connecting/connected.
 * Fields that aren't known yet are left empty. Queries the modem over AT
 * (AT+CGDCONT?/AT+CESQ), so only call it on demand, not periodically.
 * NUL-terminated, truncated to fit buf_len; returns the length the
 * untruncated string would have been (snprintf semantics). */
size_t modem_stat_format(char *buf, size_t buf_len);

/* The modem's internal temperature in whole degrees C (AT%XTEMP?) - the
 * closest thing to a core temperature the nRF9151 exposes. Returns 0 on
 * success, or a negative errno if it couldn't be read (e.g. the modem
 * library isn't initialized yet). */
int modem_core_temp(int *temp_c);

/* The websocket keepalive ping interval, in seconds - config_store's
 * "ping" (1..3600, set via control.rs's "#ping"), defaulting to 60 (and
 * persisting that default) if unset or out of range. */
uint32_t modem_ws_ping_interval_s(void);

/* Pulls up to `max_len` bytes received over the websocket since the last
 * call (FIFO order), removing them. Returns the number of bytes actually
 * copied into `buf` (0 if none are available, including when no websocket
 * is currently connected). Non-blocking. Safe to call from any thread. */
size_t modem_ws_read(uint8_t *buf, size_t max_len);

/* Queues up to `len` bytes to be sent over the websocket next time
 * websocket_supervise() (modem_task.c) gets a chance - typically within
 * MODEM_WS_RECV_TIMEOUT_MS, and only once a websocket is actually
 * connected; queued bytes just wait otherwise. Returns the number of bytes
 * actually queued, which is less than `len` if the queue doesn't have room
 * for all of it - callers aren't expected to retry the remainder (same as
 * uart_task_write(), a dropped/short write here means the peer misses part
 * of a reply, not that the caller should loop). Safe to call from any
 * thread. */
size_t modem_ws_write(const uint8_t *buf, size_t len);

#endif /* MODEM_TASK_H_ */
```
